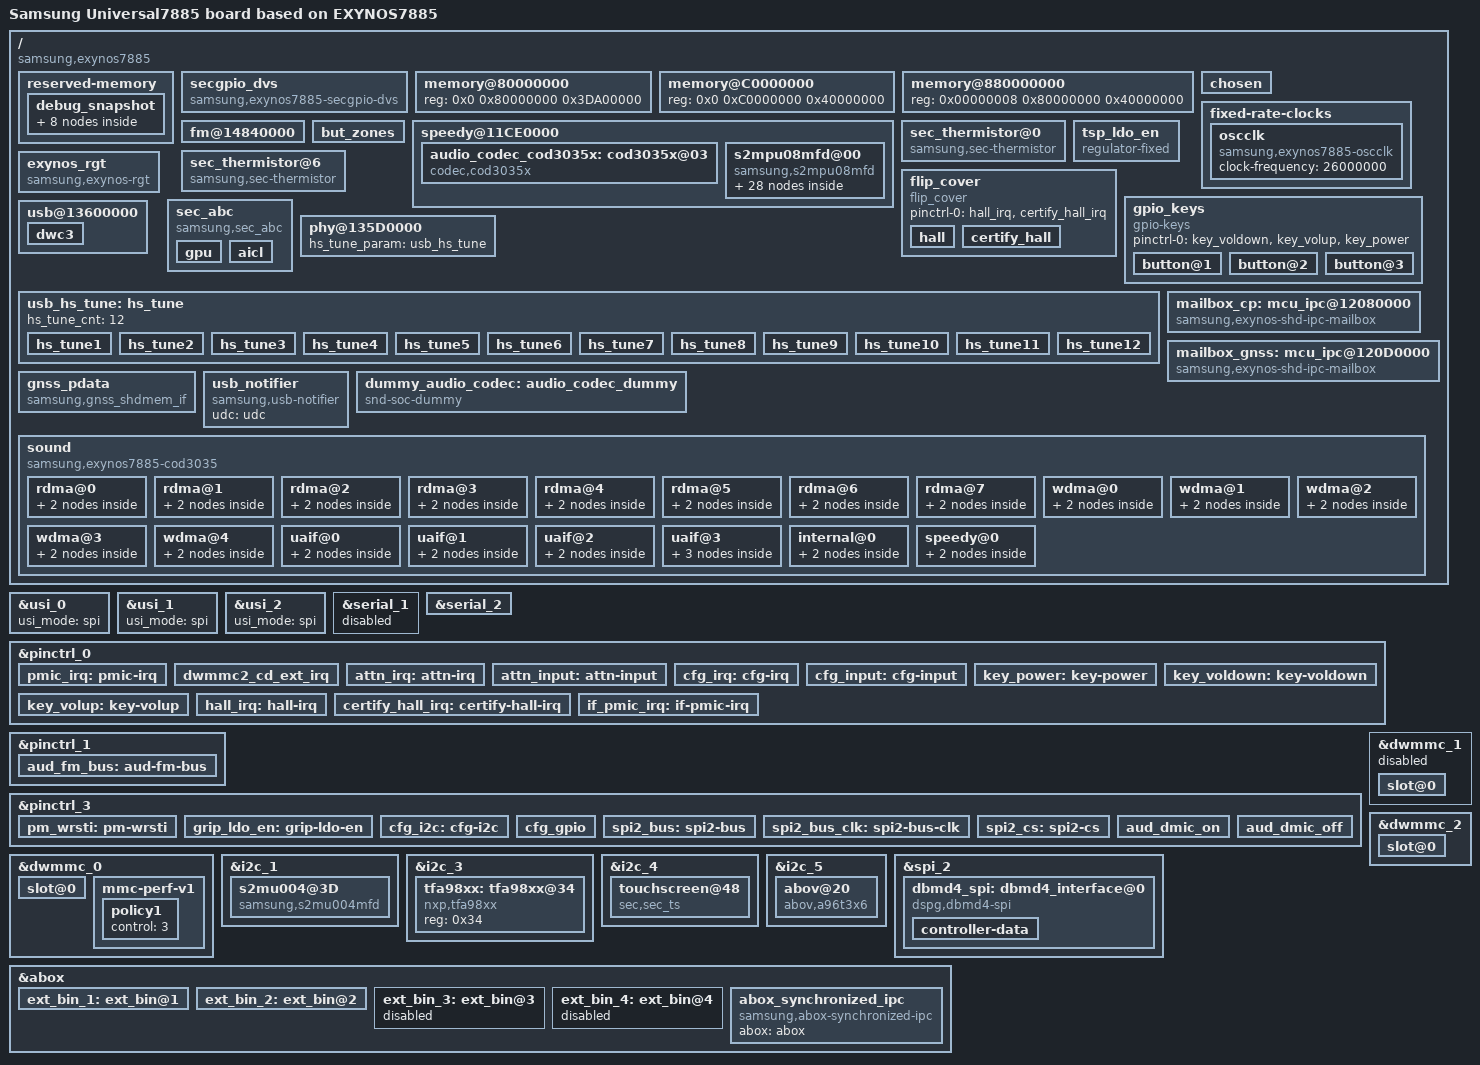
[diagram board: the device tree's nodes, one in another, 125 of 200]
/*
 * SAMSUNG UNIVERSAL7885 board device tree source
 *
 * Copyright (c) 2013 Samsung Electronics Co., Ltd.
 *		http://www.samsung.com
 *
 * This program is free software; you can redistribute it and/or modify
 * it under the terms of the GNU General Public License version 2 as
 * published by the Free Software Foundation.
*/

#define NO_DTBO
#include "exynos7885_4.4_bl.dts"
#include "display-lcd_jackpotlte_common.dtsi"
#include "modem-s327ap-sipc-pdata.dtsi"
#include "battery_data_jackpotlte_common.dtsi"
//#include "exynos7885-jackpotlte_motor.dtsi"
#include "exynos7885-mali.dtsi"

/ {
	model = "Samsung Universal7885 board based on EXYNOS7885";
	compatible = "samsung,exynos7885", "samsung,Universal7885";

	reserved-memory {
		#address-cells = <2>;
		#size-cells = <1>;
		ranges;

		debug_snapshot {
			#address-cells = <0x2>;
			#size-cells = <0x1>;

			header {
				compatible = "debug-snapshot,header";
				reg = <0x0 0x91200000 0x7000>;
			};

			log_kevents {
				compatible = "debug-snapshot,log_kevents";
				reg = <0x0 0x91207000 0x7F9000>;
			};

			log_kernel {
				compatible = "debug-snapshot,log_kernel";
				reg = <0x0 0x91A00000 0x200000>;
			};

			log_platform {
				compatible = "debug-snapshot,log_platform";
				reg = <0x0 0x91E00000 0x400000>;
			};

			log_sfr {
				compatible = "debug-snapshot,log_sfr";
				reg = <0x0 0x92200000 0x400000>;
			};

			log_cachedump {
				compatible = "debug-snapshot,log_cachedump";
				reg = <0x0 0x92600000 0x0>;
			};

			log_bcm {
				compatible = "debug-snapshot,log_bcm";
				reg = <0x0 0x92600000 0x0>;
			};

			log_pstore {
				compatible = "debug-snapshot,log_pstore";
				reg = <0x0 0x92600000 0x8000>;
			};
		};
	};

	secgpio_dvs {
		compatible = "samsung,exynos7885-secgpio-dvs";
		status = "okay";
	};

	memory@80000000 {
		device_type = "memory";
		reg = <0x0 0x80000000 0x3DA00000>;
	};

	memory@C0000000 {
		device_type = "memory";
		reg = <0x0 0xC0000000 0x40000000>;
	};

	memory@880000000 {
		device_type = "memory";
		reg = <0x00000008 0x80000000 0x40000000>;
	};

	chosen {
		bootargs = "console=ram root=/dev/ram0 clk_ignore_unused androidboot.hardware=samsungexynos7885 androidboot.selinux=permissive ess_setup=0x86000000 androidboot.debug_level=0x4948";
		linux,initrd-start = <0x84000000>;
		linux,initrd-end = <0x840FFFFF>;
	};

	fixed-rate-clocks {
		oscclk {
			compatible = "samsung,exynos7885-oscclk";
			clock-frequency = <26000000>;
		};
	};

	fm@14840000 {
		num-volume-level = <16>;
		val-vol-level = <0 11 16 23 32 45 64
				 90 128 181 256 362
				 512 724 1024 1400>;
	};

	but_zones: but_zones {
		#list-but-cells = <3>;
	};

	speedy@11CE0000 {
		status = "okay";
		audio_codec_cod3035x: cod3035x@03 {
			compatible = "codec,cod3035x";
			reg = <0x03>;
			i2c-speedy-address;
			vdd-supply = <&l36_reg>;
			pinctrl-names = "default";
			mic-bias1-voltage = <3>;
			mic-bias2-voltage = <1>;
			mic-bias-ldo-voltage = <3>;
			use-btn-adc-mode;
			use-det-gdet-adc-mode = <1>;
			jack-imp-tuning = <7>;
			io-channels = <&exynos_adc 3>,<&exynos_adc 7>;
			io-channel-names = "adc-ear","adc-gdet";
			#io-channel-cells = <1>;
			io-channel-ranges;
			but-zones-list = <&but_zones 226 0 376>,
							 <&but_zones 582 377 447>,
							 <&but_zones 115 448 627>,
							 <&but_zones 114 628 1161>;
			mic-adc-range = <1404>;
			btn-release-value = <1404>;
		};

		s2mpu08mfd@00 {
			compatible = "samsung,s2mpu08mfd";
			acpm-ipc-channel = <2>;
			i2c-speedy-address;
			s2mpu08,wakeup = "enabled";
			s2mpu08,irq-gpio = <&gpa2 0 0>;
			reg = <0x00>;
			interrupts = <2 0 0>;
			interrupt-parent = <&gpa2>;
			pinctrl-names = "default";
			pinctrl-0 = <&pmic_irq &pm_wrsti>;
			/* RTC: wtsr/smpl */
			wtsr_en = "enabled"; /* enable */
			smpl_en = "enabled"; /* enable */
			wtsr_timer_val = <3>;	/* 1000ms */
			smpl_timer_val = <0>;	/* 100ms */
			check_jigon = <0>; /* do not check jigon */
			/* RTC: If it's first boot, reset rtc to 1/1/2017 12:00:00(Sun) */
			init_time,sec = <0>;
			init_time,min = <0>;
			init_time,hour = <12>;
			init_time,mday = <1>;
			init_time,mon = <0>;
			init_time,year = <117>;
			init_time,wday = <0>;

			samsung,codec-interrupt = <&audio_codec_cod3035x>;

			regulators {
				b1_reg: BUCK1 {
					regulator-name = "vdd_mif";
					regulator-min-microvolt = <500000>;
					regulator-max-microvolt = <1100000>;
					regulator-always-on;
					regulator-ramp-delay = <12000>;
					regulator-initial-mode = <2>;
				};

				b2_reg: BUCK2 {
					regulator-name = "vdd_cpucl0";
					regulator-min-microvolt = <500000>;
					regulator-max-microvolt = <1300000>;
					regulator-always-on;
					regulator-ramp-delay = <12000>;
					regulator-initial-mode = <1>;
				};

				b3_reg: BUCK3 {
					regulator-name = "vdd_cpucl1_2";
					regulator-min-microvolt = <500000>;
					regulator-max-microvolt = <1300000>;
					regulator-always-on;
					regulator-ramp-delay = <12000>;
					regulator-initial-mode = <1>;
				};

				b4_reg: BUCK4 {
					regulator-name = "vdd_int";
					regulator-min-microvolt = <500000>;
					regulator-max-microvolt = <1200000>;
					regulator-always-on;
					regulator-ramp-delay = <12000>;
					regulator-initial-mode = <2>;
				};

				b5_reg: BUCK5 {
					regulator-name = "vdd_g3d";
					regulator-min-microvolt = <500000>;
					regulator-max-microvolt = <1300000>;
					regulator-always-on;
					regulator-ramp-delay = <12000>;
					regulator-initial-mode = <1>;
				};

				b6_reg: BUCK6 {
					regulator-name = "vdd2_mem";
					regulator-min-microvolt = <500000>;
					regulator-max-microvolt = <1300000>;
					regulator-always-on;
					regulator-ramp-delay = <12000>;
					regulator-initial-mode = <3>;
				};

				b7_reg: BUCK7 {
					regulator-name = "vdd_lldo";
					regulator-min-microvolt = <1200000>;
					regulator-max-microvolt = <1500000>;
					regulator-always-on;
					regulator-boot-on;
					regulator-ramp-delay = <12000>;
					regulator-initial-mode = <3>;
				};

				b8_reg: BUCK8 {
					regulator-name = "vdd_mldo";
					regulator-min-microvolt = <1800000>;
					regulator-max-microvolt = <2100000>;
					regulator-always-on;
					regulator-ramp-delay = <12000>;
					regulator-initial-mode = <3>;
				};

				l1_reg: LDO1 {
					regulator-name = "vdd_ldo1";
					regulator-min-microvolt = <700000>;
					regulator-max-microvolt = <1300000>;
					regulator-always-on;
					regulator-ramp-delay = <12000>;
					regulator-initial-mode = <3>;
				};

				l2_reg: LDO2 {
					regulator-name = "vqmmc";
					regulator-min-microvolt = <1800000>;
					regulator-max-microvolt = <3375000>;
					regulator-ramp-delay = <12000>;
				};

				l3_reg: LDO3 {
					regulator-name = "vdd_ldo3";
					regulator-min-microvolt = <800000>;
					regulator-max-microvolt = <1950000>;
					regulator-always-on;
					regulator-ramp-delay = <12000>;
					regulator-initial-mode = <3>;
				};

				l4_reg: LDO4 {
					regulator-name = "vdd_ldo4";
					regulator-min-microvolt = <500000>;
					regulator-max-microvolt = <1300000>;
					regulator-always-on;
					regulator-ramp-delay = <12000>;
					regulator-initial-mode = <1>;
				};

				l5_reg: LDO5 {
					regulator-name = "vdd_ldo5";
					regulator-min-microvolt = <800000>;
					regulator-max-microvolt = <1350000>;
					regulator-always-on;
					regulator-ramp-delay = <12000>;
					regulator-initial-mode = <1>;
				};

				l6_reg: LDO6 {
					regulator-name = "vdd_ldo6";
					regulator-min-microvolt = <800000>;
					regulator-max-microvolt = <1350000>;
					regulator-always-on;
					regulator-ramp-delay = <12000>;
					regulator-initial-mode = <1>;
				};

				l7_reg: LDO7 {
					regulator-name = "vdd_ldo7";
					regulator-min-microvolt = <800000>;
					regulator-max-microvolt = <1950000>;
					regulator-always-on;
					regulator-ramp-delay = <12000>;
					regulator-initial-mode = <1>;
				};

				l8_reg: LDO8 {
					regulator-name = "vdd_ldo8";
					regulator-min-microvolt = <500000>;
					regulator-max-microvolt = <1300000>;
					regulator-always-on;
					regulator-ramp-delay = <12000>;
					regulator-initial-mode = <1>;
				};

				l9_reg: LDO9 {
					regulator-name = "vdd_ldo9";
					regulator-min-microvolt = <500000>;
					regulator-max-microvolt = <1300000>;
					regulator-always-on;
					regulator-ramp-delay = <12000>;
					regulator-initial-mode = <1>;
				};

				l10_reg: LDO10 {
					regulator-name = "vdd_ldo10";
					regulator-min-microvolt = <500000>;
					regulator-max-microvolt = <1300000>;
					regulator-always-on;
					regulator-ramp-delay = <12000>;
					regulator-initial-mode = <1>;
				};

				l11_reg: LDO11 {
					regulator-name = "vdd_ldo11";
					regulator-min-microvolt = <500000>;
					regulator-max-microvolt = <1300000>;
					regulator-always-on;
					regulator-ramp-delay = <12000>;
					regulator-initial-mode = <1>;
				};

				l12_reg: LDO12 {
					regulator-name = "vdd_ldo12";
					regulator-min-microvolt = <800000>;
					regulator-max-microvolt = <1350000>;
					regulator-always-on;
					regulator-ramp-delay = <12000>;
					regulator-initial-mode = <1>;
				};

				l13_reg: LDO13 {
					regulator-name = "vdd_ldo13";
					regulator-min-microvolt = <800000>;
					regulator-max-microvolt = <1950000>;
					regulator-always-on;
					regulator-ramp-delay = <12000>;
					regulator-initial-mode = <1>;
				};

				l14_reg: LDO14 {
					regulator-name = "vdd_ldo14";
					regulator-min-microvolt = <1800000>;
					regulator-max-microvolt = <3375000>;
					regulator-always-on;
					regulator-ramp-delay = <12000>;
					regulator-initial-mode = <1>;
				};

				l33_reg: LDO33 {
					regulator-name = "vdd_ldo33";
					regulator-min-microvolt = <800000>;
					regulator-max-microvolt = <1950000>;
					regulator-always-on;
					regulator-ramp-delay = <12000>;
					regulator-initial-mode = <3>;
				};

				l34_reg: LDO34 {
					regulator-name = "vdd_ldo34";
					regulator-min-microvolt = <1800000>;
					regulator-max-microvolt = <3375000>;
					regulator-always-on;
					regulator-ramp-delay = <12000>;
					regulator-initial-mode = <3>;
				};

				l35_reg: LDO35 {
					regulator-name = "vmmc";
					regulator-min-microvolt = <1800000>;
					regulator-max-microvolt = <3000000>;
					regulator-ramp-delay = <12000>;
				};

				l36_reg: LDO36 {
					regulator-name = "vdd_ldo36";
					regulator-min-microvolt = <800000>;
					regulator-max-microvolt = <1950000>;
					regulator-always-on;
					regulator-ramp-delay = <12000>;
					regulator-initial-mode = <3>;
				};

				l37_reg: LDO37 {
					regulator-name = "vdd_ldo37";
					regulator-min-microvolt = <1800000>;
					regulator-max-microvolt = <3375000>;
					regulator-always-on;
					regulator-ramp-delay = <12000>;
					regulator-initial-mode = <3>;
				};
			};
		};
	};

	sec_thermistor@0 {
		compatible = "samsung,sec-thermistor";
		status = "okay";
		thermistor_name = "sec-ap-thermistor";
		id = <0>;

		adc_array = <235 308 378 395 467 568 603 648 698 764
				908 1066 1170 1242 1327 1430 1633 1830 2061 2282
				2409 2500 2584 2697 2880 3069 3213 3337 3447>;
		temp_array = <900 850 800 750 700 650 620 600 580 550
				500 450 420 400 380 350 300 250 200 150
				120 100 80 50 0 (-50) (-100) (-150) (-200)>;
		io-channels = <&exynos_adc 0>;
		io-channel-names = "adc-ap-temp";
		io-channel-ranges;
	};

	sec_thermistor@6 {
		compatible = "samsung,sec-thermistor";
		status = "okay";
		//cf? jackpotlte has wf
		thermistor_name = "sec-wf-thermistor";
		id = <1>;

		adc_array = <235 308 378 395 467 568 603 648 698 764
				908 1066 1170 1242 1327 1430 1633 1830 2061 2282
				2409 2500 2584 2697 2880 3069 3213 3337 3447>;
		temp_array = <900 850 800 750 700 650 620 600 580 550
				500 450 420 400 380 350 300 250 200 150
				120 100 80 50 0 (-50) (-100) (-150) (-200)>;
		io-channels = <&exynos_adc 6>;
		io-channel-names = "adc-wf-temp";
		io-channel-ranges;
	};

	exynos_rgt {
		compatible = "samsung,exynos-rgt";
	};

	tsp_ldo_en {
		compatible = "regulator-fixed";
		regulator-name = "tsp_ldo_en";
		regulator-min-microvolt = <1800000>;
		regulator-max-microvolt = <1800000>;
		gpio = <&gpg3 0 0>;
		enable-active-high;
		regulator-boot-on;
	};

	flip_cover {
		status = "okay";
		compatible = "flip_cover";
		pinctrl-names = "default";
		pinctrl-0 = <&hall_irq &certify_hall_irq>;
		hall {
			name = "hall";
			event = <0x15>;
			gpios = <&gpa0 3 0>;
		};
		certify_hall {
			name = "certify_hall";
			event = <0x1b>;
			gpios = <&gpa0 4 0xf>;
		};
	};

	gpio_keys {
		status = "okay";
		compatible = "gpio-keys";
		#address-cells = <1>;
		#size-cells = <0>;
		pinctrl-names = "default";
		pinctrl-0 = <&key_voldown &key_volup &key_power>;
		button@1 {
			label = "gpio-keys: KEY_VOLUMEDOWN";
			interrupts = <6 0 0>;
			interrupt-parent = <&gpa1>;
			linux,code = <114>;
			gpios = <&gpa1 6 0xf>;
		};
		button@2 {
			label = "gpio-keys: KEY_VOLUMEUP";
			interrupts = <5 0 0>;
			interrupt-parent = <&gpa1>;
			linux,code = <115>;
			gpios = <&gpa1 5 0xf>;
		};
		button@3 {
			label = "gpio-keys: KEY_POWER";
			interrupts = <7 0 0>;
			interrupt-parent = <&gpa1>;
			linux,code = <116>;
			gpios = <&gpa1 7 0xf>;
			gpio-key,wakeup = <1>;
		};

	};

	sec_abc {
		compatible = "samsung,sec_abc";
		status = "okay";

		gpu {
			gpu,label="GPU fault";
			gpu,threshold_count=<20>;
			gpu,threshold_time=<1200>;
		};
		aicl {
			aicl,label="battery aicl";
			aicl,threshold_count=<5>;
			aicl,threshold_time=<300>;
		};
	};

	usb@13600000 {
		status = "okay";
		dwc3 {
			dr_mode = "otg";
			maximum-speed = "high-speed";
			snps,quirk-frame-length-adjustment = <0x20>;
		};
	};

	phy@135D0000 {
		status = "okay";
		hs_tune_param = <&usb_hs_tune>;
	};

	usb_hs_tune:hs_tune {
		hs_tune_cnt = <12>;

		/* value = <device host> */
		hs_tune1 {
			tune_name = "tx_vref";
			tune_value = <0xd 0x1>;
		};

		hs_tune2 {
			tune_name = "tx_pre_emp";
			tune_value = <0x3 0x3>;
		};

		hs_tune3 {
			tune_name = "tx_pre_emp_plus";
			tune_value = <0x0 0x0>;
		};

		hs_tune4 {
			tune_name = "tx_res";
			tune_value = <0x3 0x3>;
		};

		hs_tune5 {
			tune_name = "tx_rise";
			tune_value = <0x3 0x3>;
		};

		hs_tune6 {
			tune_name = "tx_hsxv";
			tune_value = <0x3 0x3>;
		};

		hs_tune7 {
			tune_name = "tx_fsls";
			tune_value = <0x3 0x3>;
		};

		hs_tune8 {
			tune_name = "rx_sqrx";
			tune_value = <0x7 0x7>;
		};

		hs_tune9 {
			tune_name = "compdis";
			tune_value = <0x7 0x7>;
		};

		hs_tune10 {
			tune_name = "otg";
			tune_value = <0x2 0x2>;
		};

		hs_tune11 {
		/* true : 1, false: 0 */
		/* <enable_user_imp user_imp_value> */
			tune_name = "enable_user_imp";
			tune_value = <0x0 0x0>;
		};

		hs_tune12 {
		/* PHY clk : 1 , FREE clk : 0 */
			tune_name = "is_phyclock";
			tune_value = <0x1 0x1>;
		};
	};

	mailbox_cp: mcu_ipc@12080000 {
		compatible = "samsung,exynos-shd-ipc-mailbox";
		reg = <0x0 0x12080000 0x180>;
		mcu,name = "mcu_ipc_cp";
		mcu,id = <0>;
		interrupts = <0 55 0 >; /* MAILBOX_CP_TO_AP SPI Number */
	};

	mailbox_gnss: mcu_ipc@120D0000 {
		compatible = "samsung,exynos-shd-ipc-mailbox";
		reg = <0x0 0x120D0000 180>;
		mcu,name = "mcu_ipc_gnss";
		mcu,id = <1>;
		interrupts = <GIC_SPI 56 IRQ_TYPE_NONE>;
	};

	gnss_pdata {
		status = "okay";

		compatible = "samsung,gnss_shdmem_if";
		shmem,name = "KEPLER";
		shmem,device_node_name = "gnss_ipc";

		/* ACTIVE WATCHDOG WAKEUP */
		interrupts = <GIC_SPI 20 IRQ_TYPE_NONE>,
			     <GIC_SPI 165 IRQ_TYPE_NONE>,
			     <GIC_SPI 164 IRQ_TYPE_NONE>;
		interrupt-names = "ACTIVE", "WATCHDOG", "WAKEUP";

		memory-region = <&gnss_reserved>;
		mbox_info = <&mailbox_gnss>;

		mbx,int_ap2gnss_bcmd = <0>;
		mbx,int_ap2gnss_req_fault_info = <1>;
		mbx,int_ap2gnss_ipc_msg = <2>;
		mbx,int_ap2gnss_ack_wake_set = <3>;
		mbx,int_ap2gnss_ack_wake_clr = <4>;

		mbx,irq_gnss2ap_bcmd = <0>;
		mbx,irq_gnss2ap_rsp_fault_info = <1>;
		mbx,irq_gnss2ap_ipc_msg = <2>;
		mbx,irq_gnss2ap_req_wake_clr = <4>;

		mbx,reg_bcmd_ctrl = <0>, <1>, <2>, <3>;

		reg_rx_ipc_msg = <1 5>;
		reg_tx_ipc_msg = <1 4>;
		reg_rx_head = <1 3>;
		reg_rx_tail = <1 2>;
		reg_tx_head = <1 1>;
		reg_tx_tail = <1 0>;
		fault_info = <1 0x200000 0x180000>;

		shmem,ipc_offset = <0x380000>;
		shmem,ipc_size = <0x80000>;
		shmem,ipc_reg_cnt = <32>;

		/* Use the following value when can't boot with mailbox */
		shmem,boot_without_mbox = <1>; /* Default : 0 */
	};

	usb_notifier {
		compatible = "samsung,usb-notifier";
		udc = <&udc>;
	};

	dummy_audio_codec: audio_codec_dummy {
		status = "okay";
		compatible = "snd-soc-dummy";
	};

	sound {
		status = "okay";
		compatible = "samsung,exynos7885-cod3035";
		mic-bias-mode = <0 0 2 0>;
		clock-names = "xclkout";
		samsung,codec = <&abox>;

		samsung,routing =  "VOUTPUT", "ABOX UAIF0 Playback",
				 "VOUTPUTCALL", "ABOX UAIF2 Playback",
				 "ABOX UAIF2 Capture", "VINPUTCALL",
				 "ABOX SPEEDY Capture", "VINPUTFM",
				 // "SPK", "ABOX UAIF3 Playback",
				 // "ABOX UAIF3 Capture", "VI";
				 "SPK", "AIF Playback-8-34",
				 "AIF Playback-8-34", "ABOX UAIF3 Playback",
				 "ABOX UAIF3 Capture", "AIF Capture-8-34";

		rdma@0 {
			cpu {
				sound-dai = <&abox 0>;
			};
			codec {
				sound-dai = <&dummy_audio_codec>;
			};
		};
		rdma@1 {
			cpu {
				sound-dai = <&abox 1>;
			};
			codec {
				sound-dai = <&dummy_audio_codec>;
			};
		};
		rdma@2 {
			cpu {
				sound-dai = <&abox 2>;
			};
			codec {
				sound-dai = <&dummy_audio_codec>;
			};
		};
		rdma@3 {
			cpu {
				sound-dai = <&abox 3>;
			};
			codec {
				sound-dai = <&dummy_audio_codec>;
			};
		};
		rdma@4 {
			cpu {
				sound-dai = <&abox 4>;
			};
			codec {
				sound-dai = <&dummy_audio_codec>;
			};
		};
		rdma@5 {
			cpu {
				sound-dai = <&abox 5>;
			};
			codec {
				sound-dai = <&dummy_audio_codec>;
			};
		};
		rdma@6 {
			cpu {
				sound-dai = <&abox 6>;
			};
			codec {
				sound-dai = <&dummy_audio_codec>;
			};
		};
		rdma@7 {
			cpu {
				sound-dai = <&abox 7>;
			};
			codec {
				sound-dai = <&dummy_audio_codec>;
			};
		};
		wdma@0 {
			cpu {
				sound-dai = <&abox 8>;
			};
			codec {
				sound-dai = <&dummy_audio_codec>;
			};
		};
		wdma@1 {
			cpu {
				sound-dai = <&abox 9>;
			};
			codec {
				sound-dai = <&dummy_audio_codec>;
			};
		};
		wdma@2 {
			cpu {
				sound-dai = <&abox 10>;
			};
			codec {
				sound-dai = <&dummy_audio_codec>;
			};
		};
		wdma@3 {
			cpu {
				sound-dai = <&abox 11>;
			};
			codec {
				sound-dai = <&dummy_audio_codec>;
			};
		};
		wdma@4 {
			cpu {
				sound-dai = <&abox 12>;
			};
			codec {
				sound-dai = <&dummy_audio_codec>;
			};
		};
		uaif@0 {
			cpu {
				sound-dai = <&abox 13>;
			};
			codec {
				sound-dai = <&audio_codec_cod3035x>;
			};
		};
		uaif@1 {
			cpu {
				sound-dai = <&abox 14>;
			};
			codec {
				sound-dai = <&dummy_audio_codec>;
			};
		};
		uaif@2 {
			cpu {
				sound-dai = <&abox 15>;
			};
			codec {
				sound-dai = <&dummy_audio_codec>;
			};
		};
		uaif@3 {
			cpu {
				sound-dai = <&abox 16>;
			};
			platform {
				sound-dai = <&abox_synchronized_ipc 0>;
			};
			codec {
				sound-dai = <&tfa98xx 0>;
			};
		};
		internal@0 {
			cpu {
				sound-dai = <&abox 17>;
			};
			codec {
				sound-dai = <&dummy_audio_codec>;
			};
		};
		speedy@0 {
			cpu {
				sound-dai = <&abox 18>;
			};
			codec {
				sound-dai = <&dummy_audio_codec>;
			};
		};
	};
};

/* USI MODE SETTINGS

usi_mode = "hsi2c0" or "hsi2c1" or "spi" or "uart"
or "hsi2c0_hsi2c1" or "uart_hsi2c1"
*/
&usi_0 {
	usi_mode = "spi";
	status = "okay";
};

&usi_1 {
	usi_mode = "spi";
	status = "okay";
};

&usi_2 {
	usi_mode = "spi";
	status = "okay";
};

&serial_1 {
	status = "disabled";
};

&serial_2 {
	status = "okay";
};

&pinctrl_0 { //11CB0000
	pmic_irq: pmic-irq {
		samsung,pins = "gpa2-0";
		samsung,pin-pud = <3>;
		samsung,pin-drv = <3>;
	};

	dwmmc2_cd_ext_irq: dwmmc2_cd_ext_irq {
		samsung,pins = "gpa0-7";
		samsung,pin-function = <0xf>;
		samsung,pin-pud = <0>;
		samsung,pin-drv = <3>;
	};

	attn_irq: attn-irq {
		samsung,pins = "gpa0-0";
		samsung,pin-function = <0xf>;
		samsung,pin-pud = <0>;
		samsung,pin-drv = <0>;
	};
	attn_input: attn-input {
		samsung,pins = "gpa0-0";
		samsung,pin-function = <0>;
		samsung,pin-pud = <1>;
	};
	cfg_irq: cfg-irq {
		samsung,pins = "gpa2-7";
		samsung,pin-function = <0xf>;
		samsung,pin-pud = <0>;
		samsung,pin-drv = <0>;
	};
	cfg_input: cfg-input {
		samsung,pins = "gpa2-7";
		samsung,pin-function = <0>;
		samsung,pin-pud = <0>;
		samsung,pin-drv = <0>;
	};

	key_power: key-power {
		samsung,pins = "gpa1-7";
		samsung,pin-function = <0xf>;
		samsung,pin-pud = <0>;
		samsung,pin-drv = <0>;
	};

	key_voldown: key-voldown {
		samsung,pins = "gpa1-6";
		samsung,pin-function = <0xf>;
		samsung,pin-pud = <0>;
		samsung,pin-drv = <0>;
	};

	key_volup: key-volup {
		samsung,pins = "gpa1-5";
		samsung,pin-function = <0xf>;
		samsung,pin-pud = <0>;
		samsung,pin-drv = <0>;
	};

	hall_irq: hall-irq {
		samsung,pins = "gpa0-3";
		samsung,pin-function = <0xf>;
		samsung,pin-pud = <0>;
		samsung,pin-drv = <0>;
	};

	certify_hall_irq: certify-hall-irq {
		samsung,pins = "gpa0-4";
		samsung,pin-function = <0xf>;
		samsung,pin-pud = <0>;
		samsung,pin-drv = <0>;
	};

	if_pmic_irq: if-pmic-irq {
		samsung,pins = "gpa2-2";
		samsung,pin-function = <0>;
		samsung,pin-pud = <0>;
		samsung,pin-drv = <0>;
	};
};

&pinctrl_1 { //148F0000
	// Override pin-function (done in stock)
	aud_fm_bus: aud-fm-bus {
		samsung,pins = "gpb1-1", "gpb1-2", "gpb1-3";
		samsung,pin-function = <0>;
		samsung,pin-pud = <1>;
	};
};

&pinctrl_3 { //139B0000
	/* Warm reset information from AP */
	pm_wrsti: pm-wrsti {
		samsung,pins = "gpg1-1";
		samsung,pin-con-pdn = <3>;
	};

#if 0
	/* SPI_FP */
	spi1_bus_inactive: spi1-bus-inactive {
		samsung,pins = "gpp6-0", "gpp6-1", "gpp6-3";
		samsung,pin-function = <1>;
		samsung,pin-pud = <0>;
		samsung,pin-drv = <2>;
	};
	spi1_miso_inactive: spi1-miso-inactive {
		samsung,pins = "gpp6-2";
		samsung,pin-function = <0>;
		samsung,pin-pud = <1>;
		samsung,pin-drv = <2>;
	};
	spi1_clk: spi1-clk {
		samsung,pins = "gpp6-0";
		samsung,pin-function = <2>;
		samsung,pin-pud = <1>;
		samsung,pin-drv = <2>;
	};
	spi1_cs: spi1-cs {
		samsung,pins = "gpp6-1";
		samsung,pin-function = <2>;
		samsung,pin-pud = <3>;
		samsung,pin-drv = <2>;
	};
	spi1_miso: spi1-miso {
		samsung,pins = "gpp6-2";
		samsung,pin-function = <2>;
		samsung,pin-pud = <0>;
		samsung,pin-drv = <2>;
	};
	spi1_mosi: spi1-mosi {
		samsung,pins = "gpp6-3";
		samsung,pin-function = <2>;
		samsung,pin-pud = <1>;
		samsung,pin-drv = <2>;
	};

	fimc_is_flash_host: fimc-is-flash-host {
		samsung,pins = "gpg1-2";
		samsung,pin-function = <1>; /* 0: input, 1:output*/
		samsung,pin-pud = <0>; /* 0: NP, 1: PD, 2: reserved 3:PU */
		samsung,pin-drv = <0>;
	};
	fimc_is_flash_is: fimc-is-flash-is {
		samsung,pins = "gpg1-2";
		samsung,pin-function = <0>; /* 0: input, 1:output*/
		samsung,pin-pud = <1>; /* 0: NP, 1: PD, 2: reserved 3:PU */
		samsung,pin-drv = <0>;
	};
#endif

	grip_ldo_en: grip-ldo-en {
		samsung,pins = "gpg2-5";
		samsung,pin-function = <1>;
		samsung,pin-val = <1>;
		samsung,pin-pud = <0>;
		samsung,pin-con-pdn =<3>;
		samsung,pin-pud-pdn = <0>;
	};

	/* touchkey i2c*/
	cfg_i2c: cfg-i2c {
		samsung,pins = "gpp4-2", "gpp4-3";
		samsung,pin-function = <2>;
		samsung,pin-pud = <0>;
		samsung,pin-drv = <0>;
	};
	cfg_gpio: cfg_gpio {
		samsung,pins = "gpp4-2", "gpp4-3";
		samsung,pin-function = <0>;
		samsung,pin-pud = <0>;
		samsung,pin-drv = <0>;
	};

	spi2_bus: spi2-bus {
		samsung,pins = "gpc2-1", "gpc2-0";
		samsung,pin-function = <2>;
		samsung,pin-con-pdn = <3>;
		samsung,pin-pud = <1>;
		samsung,pin-pud-pdn = <0>;
		samsung,pin-drv = <0>;
	};

	spi2_bus_clk: spi2-bus-clk {
		samsung,pins = "gpc2-3";
		samsung,pin-function = <2>;
		samsung,pin-con-pdn = <3>;
		samsung,pin-pud = <0>;
		samsung,pin-pud-pdn = <0>;
		samsung,pin-drv = <0>;
		samsung,pin-val = <0>;
	};

	spi2_cs: spi2-cs {
		samsung,pins = "gpc2-2";
		samsung,pin-function = <2>;
		samsung,pin-con-pdn = <3>;
		samsung,pin-pud = <3>;
		samsung,pin-pud-pdn = <0>;
		samsung,pin-drv = <0>;
	};

	// Override off val (done in stock but wtf?)
	aud_dmic_on: aud_dmic_on {
		samsung,pins = "gpg2-1";
		samsung,pin-function = <1>;
		samsung,pin-con-pdn = <3>;
		samsung,pin-val = <1>;
	};

	aud_dmic_off: aud_dmic_off {
		samsung,pins = "gpg2-1";
		samsung,pin-function = <1>;
		samsung,pin-con-pdn = <3>;
		samsung,pin-val = <1>;
	};
};

&dwmmc_0 {
	status = "okay";
	num-slots = <1>;
	broken-cd;
	fixed_voltage;
	supports-highspeed;
	mmc-ddr-1_8v;
//	mmc-hs200-1_8v;
//	mmc-hs400-1_8v;
	supports-8bit;
	supports-cmd23;
	supports-erase;
//	supports-hs400-enhanced-strobe;
	card-init-hwacg-ctrl;
	support-cmdq;
	qos-dvfs-level = <100000>;
	fifo-depth = <0x40>;
	non-removable;
	desc-size = <4>;
	card-detect-delay = <200>;
	samsung,dw-mshc-ciu-div = <3>;
	samsung,dw-mshc-txdt-crc-timer-fastlimit = <0x13>;
	samsung,dw-mshc-txdt-crc-timer-initval = <0x15>;
	samsung,dw-mshc-hs400-delay-line = <0x60>;
	samsung,dw-mshc-sdr-timing = <3 0 4 0>;
	samsung,dw-mshc-ddr-timing = <3 0 4 2>;
	samsung,dw-mshc-hs200-timing = <3 0 3 0>;
	samsung,dw-mshc-hs400-timing = <1 0 2 0>;
	samsung,dw-mshc-hs400-ulp-timing = <3 0 2 0>;

	num-ref-clks = <12>;
	ciu_clkin = <25 50 50 25 50 100 200 50 50 200 200 200>;

	/* Swapping clock drive strength */
	clk-drive-number = <4>;
	pinctrl-names = "default",
		"fast-slew-rate-1x",
		"fast-slew-rate-2x",
		"fast-slew-rate-3x",
		"fast-slew-rate-4x";
	pinctrl-0 = <&sd0_clk &sd0_cmd &sd0_rdqs &sd0_bus1 &sd0_bus4 &sd0_bus8>;
	pinctrl-1 = <&sd0_clk_fast_slew_rate_1x>;
	pinctrl-2 = <&sd0_clk_fast_slew_rate_2x>;
	pinctrl-3 = <&sd0_clk_fast_slew_rate_3x>;
	pinctrl-4 = <&sd0_clk_fast_slew_rate_4x>;
	slot@0 {
		reg = <0>;
		bus-width = <8>;
	};

	//Dunno, took this from a10eu 4.14
	mmc-perf-v1 {
		update = <0>;
		policy-num = <1>;

		policy1 {
			control = <3>;
		};
	};

};

&dwmmc_1 {
	status = "disabled";
	num-slots = <1>;
	channel = <1>;
	fixed_voltage;
	enable-cclk-on-suspend;
	caps-control;
	supports-highspeed;
	supports-4bit;
	keep-power-in-suspend;
	pm-ignore-notify;
	card-detect-type-external;
	use-broken-voltage;
	fifo-depth = <0x40>;
	card-detect-delay = <200>;
	qos-dvfs-level = <100000>;
	data-timeout = <200>;
	hto-timeout = <80>;
	samsung,dw-mshc-ciu-div = <3>;
	samsung,dw-mshc-sdr-timing = <3 0 2 0>;
	samsung,dw-mshc-ddr-timing = <3 0 2 1>;
	samsung,dw-mshc-sdr50-timing = <3 0 4 2>;
	samsung,dw-mshc-sdr104-timing = <3 0 3 0>;

	num-ref-clks = <9>;
	ciu_clkin = <25 50 50 25 50 100 200 50 50>;

	clk-drive-number = <4>;
	pinctrl-names = "default",
		"fast-slew-rate-1x",
		"fast-slew-rate-2x",
		"fast-slew-rate-3x",
		"fast-slew-rate-4x";
	pinctrl-0 = <&sd1_clk &sd1_cmd &sd1_bus1 &sd1_bus4>;
	pinctrl-1 = <&sd1_clk_fast_slew_rate_1x>;
	pinctrl-2 = <&sd1_clk_fast_slew_rate_2x>;
	pinctrl-3 = <&sd1_clk_fast_slew_rate_3x>;
	pinctrl-4 = <&sd1_clk_fast_slew_rate_4x>;
	slot@0 {
		reg = <0>;
		bus-width = <4>;
	};
};

&dwmmc_2 {
	status = "okay";
	num-slots = <1>;
	supports-4bit;
	supports-cmd23;
	supports-erase;
	supports-highspeed;
	sd-uhs-sdr50;
	sd-uhs-sdr104;
	card-detect-gpio;
	card-no-pre-powerup;
	bypass-for-allpass;
	card-init-hwacg-ctrl;
	skip-init-mmc-scan;
	qos-dvfs-level = <100000>;
	qos-sd3-dvfs-level = <267000>;
	fifo-depth = <0x40>;
	desc-size = <4>;
	card-detect-delay = <200>;
	data-timeout = <200>;
	hto-timeout = <80>;
	samsung,dw-mshc-ciu-div = <3>;
	clock-frequency = <800000000>;
	samsung,dw-mshc-sdr-timing = <3 0 2 0>;
	samsung,dw-mshc-ddr-timing = <3 0 2 1>;
	samsung,dw-mshc-sdr50-timing = <3 0 4 2>;
	samsung,dw-mshc-sdr104-timing = <3 0 3 0>;

	num-ref-clks = <9>;
	ciu_clkin = <25 50 50 25 50 100 200 50 50>;

	/* Swapping clock drive strength */
	clk-drive-number = <4>;
	pinctrl-names = "default",
		"fast-slew-rate-1x",
		"fast-slew-rate-2x",
		"fast-slew-rate-3x",
		"fast-slew-rate-4x";
	pinctrl-0 = <&sd2_clk &sd2_cmd &sd2_bus1 &sd2_bus4 &dwmmc2_cd_ext_irq>;
	pinctrl-1 = <&sd2_clk_fast_slew_rate_1x>;
	pinctrl-2 = <&sd2_clk_fast_slew_rate_2x>;
	pinctrl-3 = <&sd2_clk_fast_slew_rate_3x>;
	pinctrl-4 = <&sd2_clk_fast_slew_rate_4x>;

	card-detect = <&gpa0 7 0xf>;
	sec-sd-slot-type = <2>; /* Hybrid Tray SD slot */

	slot@0 {
		reg = <0>;
		bus-width = <4>;
		disable-wp;
	};

};

&i2c_1 {
	status = "okay";
	s2mu004@3D {
		status = "okay";
		compatible = "samsung,s2mu004mfd";
		reg = <0x3D>;
		pinctrl-names = "default";
		pinctrl-0 = <&if_pmic_irq>;
		s2mu004,irq-gpio = <&gpa2 2 1>;
		s2mu004,wakeup;
	};
};

&i2c_3 {
	status = "okay";
	tfa98xx: tfa98xx@34 {
		compatible = "nxp,tfa98xx";
		#sound-dai-cells = <1>;
		reg = <0x34>;
	};
};

&i2c_4 {
	status = "okay";
	#address-cells = <1>;
	#size-cells = <0>;
	samsung,i2c-sda-delay = <100>;
	samsung,i2c-max-bus-freq = <400000>;
	samsung,stop-after-trans;	/* LSI IC ONLY */
	touchscreen@48 {
		compatible = "sec,sec_ts";
		reg = <0x48>;
		pinctrl-names = "on_state", "off_state";
		pinctrl-0 = <&attn_irq>;
		pinctrl-1 = <&attn_input>;
		sec,tsp-id_gpio = <&gpg3 6 0>;
		sec,irq_gpio = <&gpa0 0 0>;
		sec,irq_type = <8200>;
		sec,num_lines = <30 15>;        /* rx tx */
		sec,max_coords = <4096 4096>;   /* x y */
		sec,use_ic_resolution;
		sec,mis_cal_check = <1>;
		sec,use_gpio_ldo;
		sec,regulator_avdd = "tsp_ldo_en";
		sec,regulator_boot_on;
		sec,grip_area = <512>;
		sec,bringup = <3>;
		sec,project_name = "JACKPOT1", "A530";
		sec,firmware_name = "tsp_sec/y661_a5y18.fw", "tsp_sec/y661_a5y18.fw";
		sec,tclm_level = <2>;
		sec,afe_base = <0x05>;
		status = "okay";
	};
};

//TODO driver!
&i2c_5 {
	status = "okay";
	#address-cells = <1>;
	#size-cells = <0>;
	samsung,i2c-sda-delay = <100>;
	samsung,i2c-max-bus-freq = <400000>;
	pinctrl-names = "default","on_i2c","off_i2c";
	pinctrl-0 = <&cfg_i2c>;
	pinctrl-1 = <&cfg_i2c>;
	pinctrl-2 = <&cfg_gpio>;
	abov@20 {
		status = "okay";
		compatible = "abov,a96t3x6";
		pinctrl-names = "on_irq", "off_irq";
		pinctrl-0 = <&cfg_irq &grip_ldo_en>;
		pinctrl-1 = <&cfg_input>;
		reg = <0x20>;
		abov,sda-gpio = <&gpp4 2 0>;
		abov,scl-gpio = <&gpp4 3 0>;
		abov,irq-gpio = <&gpa2 7 0>;
		abov,tkey_en-gpio = <&gpg2 5 0>;
		abov,firmware_name = "abov/a96t326_a5y18.fw";
		abov,firmup_cmd = <0x32>;
		abov,ta-notifier;
		abov,not_support_key;
		abov,bringup = <0>;
	};
};

&spi_2 {
	#address-cells = <1>;
	#size-cells = <0>;
	num-cs = <1>;

	/delete-property/ dma-mode;
	/delete-property/ dmas;
	/delete-property/ dma-names;

	pinctrl-names = "default";
	pinctrl-0 = <&spi2_bus &spi2_bus_clk &spi2_cs>;
	status = "okay";

	//TODO driver
	dbmd4_spi: dbmd4_interface@0 {
		compatible = "dspg,dbmd4-spi";
		reg = <0x0>;
		spi-max-frequency = <1000000>;
		read-chunk-size = <0x2000>;
		write-chunk-size = <0x40000>;

		interrupts = <2 0 0>;
		interrupt-parent = <&gpa0>;

		gpio-controller;
		#gpio-cells = <2>;

		controller-data {
			cs-gpio = <&gpc2 2 0>;
			samsung,spi-feedback-delay = <0>;
		};
	};
};

&abox {
	ext_bin_1: ext_bin@1 {
		status = "okay";
		samsung,name = "AP_AUDIO_SLSI.bin";
		samsung,area = <1>;
		samsung,offset = <0x7F0000>;
	};

	ext_bin_2: ext_bin@2 {
		status = "okay";
		samsung,name = "APBargeIn_AUDIO_SLSI.bin";
		samsung,area = <1>;
		samsung,offset = <0x7EC000>;
	};
	ext_bin_3: ext_bin@3 {
		status = "disabled";
		samsung,name = "spkamp.bin";
		samsung,area = <1>;
		samsung,offset = <0x502000>;
	};
	ext_bin_4: ext_bin@4 {
		status = "disabled";
		samsung,name = "param_ti.bin";
		samsung,area = <1>;
		samsung,offset = <0x600000>;
	};

	//Following comment is from original a8 source, wat?
	/* CAUTION:
	* "try to asrc off" quirk must be in dts.
	* It shouldn't be applied already audio tuned device,
	* because it changes delay and causes re-tune.
	*/
	/*
	* TODO: enable later
	*/
	/* quirks = "try to asrc off"; */

	abox_synchronized_ipc: abox_synchronized_ipc {
		compatible = "samsung,abox-synchronized-ipc";
		#sound-dai-cells = <1>;
		abox = <&abox>;
	};

};

//TODO add everything else
